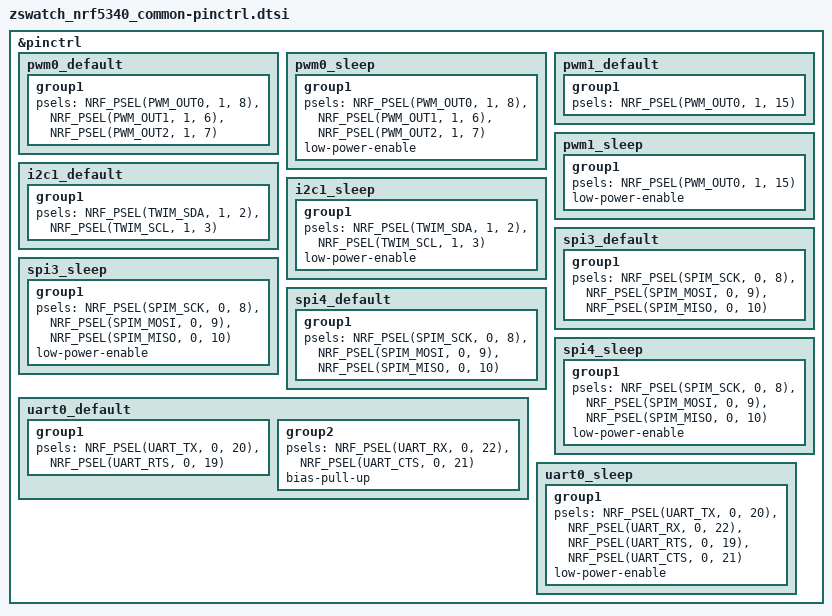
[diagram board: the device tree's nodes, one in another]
/*
 * Copyright (c) 2023 Jakob Krantz
 * SPDX-License-Identifier: Apache-2.0
 */

&pinctrl {
	pwm0_default: pwm0_default {
		group1 {
			psels = <NRF_PSEL(PWM_OUT0, 1, 8)>,
				<NRF_PSEL(PWM_OUT1, 1, 6)>,
				<NRF_PSEL(PWM_OUT2, 1, 7)>;
		};
	};

	pwm0_sleep: pwm0_sleep {
		group1 {
			psels = <NRF_PSEL(PWM_OUT0, 1, 8)>,
				<NRF_PSEL(PWM_OUT1, 1, 6)>,
				<NRF_PSEL(PWM_OUT2, 1, 7)>;
			low-power-enable;
		};
	};

	pwm1_default: pwm1_default {
		group1 {
			psels = <NRF_PSEL(PWM_OUT0, 1, 15)>;
		};
	};

	pwm1_sleep: pwm1_sleep {
		group1 {
			psels = <NRF_PSEL(PWM_OUT0, 1, 15)>;
			low-power-enable;
		};
	};

	i2c1_default: i2c1_default {
		group1 {
			psels = <NRF_PSEL(TWIM_SDA, 1, 2)>,
				<NRF_PSEL(TWIM_SCL, 1, 3)>;
		};
	};

	i2c1_sleep: i2c1_sleep {
		group1 {
			psels = <NRF_PSEL(TWIM_SDA, 1, 2)>,
				<NRF_PSEL(TWIM_SCL, 1, 3)>;
			low-power-enable;
		};
	};

	spi3_default: spi3_default {
		group1 {
			psels = <NRF_PSEL(SPIM_SCK, 0, 8)>,
				<NRF_PSEL(SPIM_MOSI, 0, 9)>,
				<NRF_PSEL(SPIM_MISO, 0, 10)>;
		};
	};

	spi3_sleep: spi3_sleep {
		group1 {
			psels = <NRF_PSEL(SPIM_SCK, 0, 8)>,
				<NRF_PSEL(SPIM_MOSI, 0, 9)>,
				<NRF_PSEL(SPIM_MISO, 0, 10)>;
			low-power-enable;
		};
	};

	spi4_default: spi4_default {
		group1 {
			psels = <NRF_PSEL(SPIM_SCK, 0, 8)>,
				<NRF_PSEL(SPIM_MOSI, 0, 9)>,
				<NRF_PSEL(SPIM_MISO, 0, 10)>;
		};
	};

	spi4_sleep: spi4_sleep {
		group1 {
			psels = <NRF_PSEL(SPIM_SCK, 0, 8)>,
				<NRF_PSEL(SPIM_MOSI, 0, 9)>,
				<NRF_PSEL(SPIM_MISO, 0, 10)>;
			low-power-enable;
		};
	};

	uart0_default: uart0_default {
		group1 {
			psels = <NRF_PSEL(UART_TX, 0, 20)>,
				<NRF_PSEL(UART_RTS, 0, 19)>;
		};
		group2 {
			psels = <NRF_PSEL(UART_RX, 0, 22)>,
				<NRF_PSEL(UART_CTS, 0, 21)>;
			bias-pull-up;
		};
	};

	uart0_sleep: uart0_sleep {
		group1 {
			psels = <NRF_PSEL(UART_TX, 0, 20)>,
				<NRF_PSEL(UART_RX, 0, 22)>,
				<NRF_PSEL(UART_RTS, 0, 19)>,
				<NRF_PSEL(UART_CTS, 0, 21)>;
			low-power-enable;
		};
	};
};
